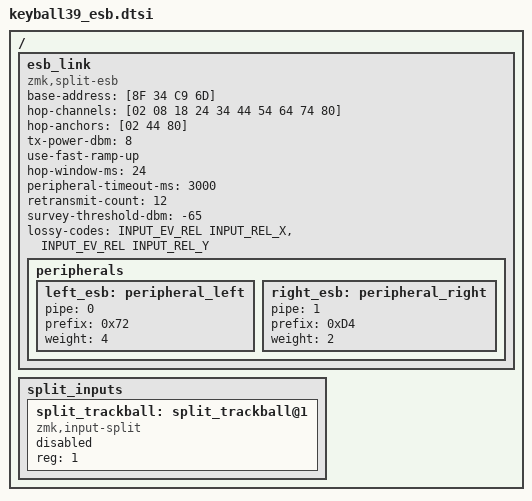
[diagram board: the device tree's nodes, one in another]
#include <zephyr/dt-bindings/input/input-event-codes.h>

/ {
    esb_link {
        compatible = "zmk,split-esb";
        base-address = [8F 34 C9 6D];
        hop-channels = [02 08 18 24 34 44 54 64 74 80];
        hop-anchors = [02 44 80];
        tx-power-dbm = <8>;
        use-fast-ramp-up;
        hop-window-ms = <24>;
        peripheral-timeout-ms = <3000>;
        retransmit-count = <12>;
        survey-threshold-dbm = <-65>;
        lossy-codes
            = <INPUT_EV_REL INPUT_REL_X>
            , <INPUT_EV_REL INPUT_REL_Y>
            ;

        peripherals {
            left_esb: peripheral_left {
                pipe = <0>;
                prefix = <0x72>;
                weight = <4>;
            };

            right_esb: peripheral_right {
                pipe = <1>;
                prefix = <0xD4>;
                weight = <2>;
            };
        };
    };

    split_inputs {
        #address-cells = <1>;
        #size-cells = <0>;

        split_trackball: split_trackball@1 {
            compatible = "zmk,input-split";
            reg = <1>;
            status = "disabled";
        };
    };
};
